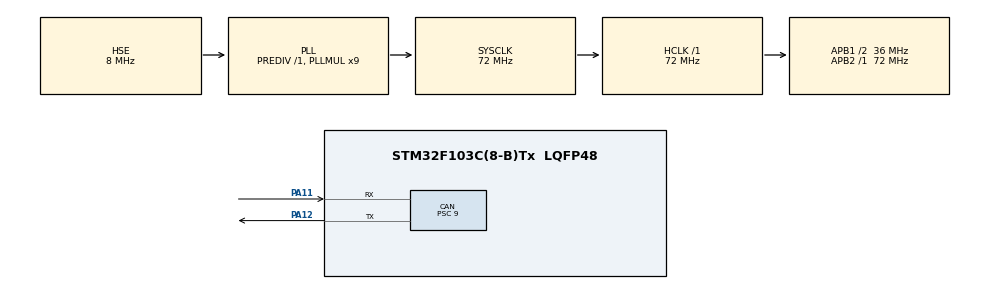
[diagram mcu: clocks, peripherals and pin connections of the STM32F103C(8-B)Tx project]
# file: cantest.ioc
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CAN.BS1=CAN_BS1_2TQ
CAN.CalculateBaudRate=1000000
CAN.CalculateTimeBit=1000
CAN.CalculateTimeQuantum=250.0
CAN.Prescaler=9
Mcu.Family=STM32F1
Mcu.Name=STM32F103C(8-B)Tx
Mcu.Package=LQFP48
NVIC.PriorityGroup=NVIC_PRIORITYGROUP_4
NVIC.TIM3_IRQn=true\:0\:0\:false\:false\:true\:true\:true\:true
NVIC.TIM4_IRQn=true\:0\:0\:false\:false\:true\:true\:true\:true
NVIC.USB_HP_CAN1_TX_IRQn=true\:0\:0\:false\:false\:true\:true\:true\:true
NVIC.USB_LP_CAN1_RX0_IRQn=true\:0\:0\:false\:false\:true\:true\:true\:true
PA11.Mode=CAN_Activate
PA11.Signal=CAN_RX
PA12.Mode=CAN_Activate
PA12.Signal=CAN_TX
PA13.Mode=Serial_Wire
PA13.Signal=SYS_JTMS-SWDIO
PA14.Mode=Serial_Wire
PA14.Signal=SYS_JTCK-SWCLK
PD0-OSC_IN.Mode=HSE-External-Oscillator
PD0-OSC_IN.Signal=RCC_OSC_IN
PD1-OSC_OUT.Mode=HSE-External-Oscillator
PD1-OSC_OUT.Signal=RCC_OSC_OUT
ProjectManager.HeapSize=0x200
ProjectManager.StackSize=0x400
ProjectManager.TargetToolchain=STM32CubeIDE
RCC.AHBFreq_Value=72000000
RCC.APB1CLKDivider=RCC_HCLK_DIV2
RCC.APB1Freq_Value=36000000
RCC.APB1TimFreq_Value=72000000
RCC.APB2Freq_Value=72000000
RCC.APB2TimFreq_Value=72000000
RCC.HCLKFreq_Value=72000000
RCC.PLLMUL=RCC_PLL_MUL9
RCC.PLLSourceVirtual=RCC_PLLSOURCE_HSE
RCC.SYSCLKFreq_VALUE=72000000
RCC.SYSCLKSource=RCC_SYSCLKSOURCE_PLLCLK
RCC.USBFreq_Value=72000000
TIM3.Period=2000
TIM3.Prescaler=72-1
TIM4.Period=2000-1
TIM4.Prescaler=71
VP_TIM3_VS_ClockSourceINT.Mode=Internal
VP_TIM4_VS_ClockSourceINT.Mode=Internal
board=custom

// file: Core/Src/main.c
/* USER CODE BEGIN Header */
/**
  ******************************************************************************
  * @file           : main.c
  * @brief          : Main program body
  ******************************************************************************
  * @attention
  *
  * Copyright (c) 2025 STMicroelectronics.
  * All rights reserved.
  *
  * This software is licensed under terms that can be found in the LICENSE file
  * in the root directory of this software component.
  * If no LICENSE file comes with this software, it is provided AS-IS.
  *
  ******************************************************************************
  */
/* USER CODE END Header */
#include "main.h"

/* USER CODE BEGIN Includes */
#include "string.h"
#include "kinematic.h"
/* USER CODE END Includes */

/* USER CODE BEGIN PTD */
typedef struct{
	int8_t FL;
	int8_t FR;
	int8_t RL;
	int8_t RR;
}Dwheel;
/* USER CODE END PTD */

/* USER CODE BEGIN PM */
//receive canbus data
uint8_t rxData[8];

//trasmit canbus data
int32_t TxMailbox;
int8_t tx_123[8];
int8_t tx_124[8];
int8_t can_tx[8]={0};

/* Pose to send */ //example data send
float pose_x = 1.23f;
float pose_y = 4.56f;
float pose_theta = 7.89f;

//wheel speed
float wheel_speed[4];
float vx=0.0f, vy =0.0f,omega =0.0f,r =0.122f;
float x=0.0f,y=0.0f,theta =0.0f;
float x_dir=0.0f,y_dir=0.0f,theta_dir =0.0f;
volatile Dwheel can;
uint8_t state =1;
/* USER CODE END PM */

CAN_HandleTypeDef hcan;

TIM_HandleTypeDef htim3;
TIM_HandleTypeDef htim4;

/* USER CODE BEGIN PV */

CAN_RxHeaderTypeDef RxHeader;
CAN_TxHeaderTypeDef TxHeader;

OMNIWHEEL omni;
CONTROLLER controller;
CONTROL_POSE pose_dir;

/* USER CODE END PV */

void SystemClock_Config(void);
static void MX_GPIO_Init(void);
static void MX_CAN_Init(void);
static void MX_TIM3_Init(void);
static void MX_TIM4_Init(void);

/* USER CODE BEGIN 0 */
void can_data_send(void){
	Dwheel can ={
		.FL =(int8_t)(wheel_speed[0]/6),
		.RL =(int8_t)(wheel_speed[2]/6),
		.FR =(int8_t)(wheel_speed[1]/6),
		.RR =(int8_t)(wheel_speed[3]/6),
	};
	TxHeader.StdId = 0x001;
	TxHeader.DLC = 8;
	memcpy(can_tx,&can, sizeof(Dwheel));
	HAL_CAN_AddTxMessage(&hcan, &TxHeader, can_tx, &TxMailbox);
}
void HAL_CAN_RxFifo0MsgPendingCallback(CAN_HandleTypeDef *hcan)
{
    CAN_RxHeaderTypeDef rxHeader;

    if (HAL_CAN_GetRxMessage(hcan, CAN_RX_FIFO0, &rxHeader, rxData) == HAL_OK)
    {
        if (rxHeader.StdId == 0x123 && rxHeader.DLC == 8)
        {
            // First frame: x, y
            memcpy(&x, &rxData[0], 4);
            memcpy(&y, &rxData[4], 4);
        }

        if (rxHeader.StdId == 0x124 && rxHeader.DLC == 4)
        {
            // Second frame: theta
            memcpy(&theta, &rxData[0], 4);
        }
    }
}

void HAL_TIM_PeriodElapsedCallback(TIM_HandleTypeDef* htim){
	if(htim->Instance == TIM3){
	controller.vx = vx;
	controller.vy = vy;
	controller.omega = omega;
	pose_dir.x=x_dir;
	pose_dir.y=y_dir;
	pose_dir.theta=theta_dir;

	omni45_kinematic2(&controller, &omni, wheel_speed);
	//omni45_kinematic_pose(&pose_dir, &omni, wheel_speed);
	}
	if(htim->Instance == TIM4){
//		TxHeader.StdId = 0x123;
//		TxHeader.DLC = 8;
//	    memcpy(&tx_123[0], &pose_x, 4);
//	    memcpy(&tx_123[4], &pose_y, 4);
//	    HAL_CAN_AddTxMessage(&hcan, &TxHeader, tx_123, &TxMailbox);
//	    TxHeader.StdId = 0x124;
//	    TxHeader.DLC = 4;
//	    memcpy(&tx_124[0], &pose_theta, 4);
//	    HAL_CAN_AddTxMessage(&hcan, &TxHeader, tx_124, &TxMailbox);
		can_data_send();
	}

}

/* USER CODE END 0 */

int main(void)
{

  /* MCU Configuration--------------------------------------------------------*/

  /* Reset of all peripherals, Initializes the Flash interface and the Systick. */
  HAL_Init();

  /* Configure the system clock */
  SystemClock_Config();

  /* Initialize all configured peripherals */
  MX_GPIO_Init();
  MX_CAN_Init();
  MX_TIM3_Init();
  MX_TIM4_Init();
  /* USER CODE BEGIN 2 */

  HAL_CAN_Start(&hcan);
  HAL_TIM_Base_Start_IT(&htim3);
  HAL_TIM_Base_Start_IT(&htim4);
  HAL_CAN_ActivateNotification(&hcan, CAN_IT_RX_FIFO0_MSG_PENDING);
  //test_omni_set_motor_speed_90(&omni, &controller, wheel_speed);
  omni_init(&omni);

  TxHeader.IDE   = CAN_ID_STD;  // Standard ID
  TxHeader.RTR   = CAN_RTR_DATA;

  /* USER CODE END 2 */

  /* Infinite loop */
  while (1)
  {

    /* USER CODE BEGIN 3 */

	/* if (state == 1){
		 //HAL_Delay(500);
		 vx = 0;
		 vy =0;
		 omega =0;
		 HAL_Delay(1000);

	 }
	 else if(state == 2){
		 vx = 2;
		 vy =0;
		 omega =0;\
		 HAL_Delay(1000);
	 }
	 else if(state ==3 ){
		 vx = 0;
		 vy =2;
	     omega =0;}

*/
	  vx = 0;
	  vy =0;
	  omega =0;
	  HAL_Delay(5000);
//	  vx = 0.4;
//	  vy =0;
//	  omega =0;
//	  HAL_Delay(500);
//	  vx = 0.88;
//	  vy =0;
//	  omega =0;
//	  HAL_Delay(500);

	  vx = 0.5;
	  vy =0;
	  omega =3.14/1.37;
	  HAL_Delay(2000);
/*
	 	  vx = -0.8;
	 	  vy =-0.8;
	 	  omega =0;
	 HAL_Delay(2000);

//	 	  vx = 0.44;
//	 	  vy =0;
//	 	  omega =0;
//	 	  HAL_Delay(500);
	  vx = 0.8;
	 	  vy =0.8;
	 	  omega =0;
	 HAL_Delay(2000);
	  vx = -0.8;
	 	  vy =0.8;
	 	  omega =0;
	 HAL_Delay(2000);*/

	 	vx = 0;
	 	vy =0;
	 	omega =0;
	 HAL_Delay(2000);

  }
  /* USER CODE END 3 */
}

void SystemClock_Config(void)
{
  RCC_OscInitTypeDef RCC_OscInitStruct = {0};
  RCC_ClkInitTypeDef RCC_ClkInitStruct = {0};

  /** Initializes the RCC Oscillators according to the specified parameters
  * in the RCC_OscInitTypeDef structure.
  */
  RCC_OscInitStruct.OscillatorType = RCC_OSCILLATORTYPE_HSE;
  RCC_OscInitStruct.HSEState = RCC_HSE_ON;
  RCC_OscInitStruct.HSEPredivValue = RCC_HSE_PREDIV_DIV1;
  RCC_OscInitStruct.HSIState = RCC_HSI_ON;
  RCC_OscInitStruct.PLL.PLLState = RCC_PLL_ON;
  RCC_OscInitStruct.PLL.PLLSource = RCC_PLLSOURCE_HSE;
  RCC_OscInitStruct.PLL.PLLMUL = RCC_PLL_MUL9;
  if (HAL_RCC_OscConfig(&RCC_OscInitStruct) != HAL_OK)
  {
    Error_Handler();
  }

  /** Initializes the CPU, AHB and APB buses clocks
  */
  RCC_ClkInitStruct.ClockType = RCC_CLOCKTYPE_HCLK|RCC_CLOCKTYPE_SYSCLK
                              |RCC_CLOCKTYPE_PCLK1|RCC_CLOCKTYPE_PCLK2;
  RCC_ClkInitStruct.SYSCLKSource = RCC_SYSCLKSOURCE_PLLCLK;
  RCC_ClkInitStruct.AHBCLKDivider = RCC_SYSCLK_DIV1;
  RCC_ClkInitStruct.APB1CLKDivider = RCC_HCLK_DIV2;
  RCC_ClkInitStruct.APB2CLKDivider = RCC_HCLK_DIV1;

  if (HAL_RCC_ClockConfig(&RCC_ClkInitStruct, FLASH_LATENCY_2) != HAL_OK)
  {
    Error_Handler();
  }
}

static void MX_CAN_Init(void)
{

  hcan.Instance = CAN1;
  hcan.Init.Prescaler = 9;
  hcan.Init.Mode = CAN_MODE_NORMAL;
  hcan.Init.SyncJumpWidth = CAN_SJW_1TQ;
  hcan.Init.TimeSeg1 = CAN_BS1_2TQ;
  hcan.Init.TimeSeg2 = CAN_BS2_1TQ;
  hcan.Init.TimeTriggeredMode = DISABLE;
  hcan.Init.AutoBusOff = DISABLE;
  hcan.Init.AutoWakeUp = DISABLE;
  hcan.Init.AutoRetransmission = DISABLE;
  hcan.Init.ReceiveFifoLocked = DISABLE;
  hcan.Init.TransmitFifoPriority = DISABLE;
  if (HAL_CAN_Init(&hcan) != HAL_OK)
  {
    Error_Handler();
  }
  /* USER CODE BEGIN CAN_Init 2 */
  CAN_FilterTypeDef filter;

    filter.FilterActivation = ENABLE;
    filter.FilterBank = 0;
    filter.FilterFIFOAssignment = CAN_FILTER_FIFO0;
    filter.FilterIdHigh = 0x0000;
    filter.FilterIdLow = 0x0000;
    filter.FilterMaskIdHigh = 0x0000;
    filter.FilterMaskIdLow = 0x0000;
    filter.FilterMode = CAN_FILTERMODE_IDMASK;
    filter.FilterScale = CAN_FILTERSCALE_32BIT;

    HAL_CAN_ConfigFilter(&hcan, &filter);
  /* USER CODE END CAN_Init 2 */

}

static void MX_TIM3_Init(void)
{

  TIM_ClockConfigTypeDef sClockSourceConfig = {0};
  TIM_MasterConfigTypeDef sMasterConfig = {0};

  htim3.Instance = TIM3;
  htim3.Init.Prescaler = 72-1;
  htim3.Init.CounterMode = TIM_COUNTERMODE_UP;
  htim3.Init.Period = 2000;
  htim3.Init.ClockDivision = TIM_CLOCKDIVISION_DIV1;
  htim3.Init.AutoReloadPreload = TIM_AUTORELOAD_PRELOAD_DISABLE;
  if (HAL_TIM_Base_Init(&htim3) != HAL_OK)
  {
    Error_Handler();
  }
  sClockSourceConfig.ClockSource = TIM_CLOCKSOURCE_INTERNAL;
  if (HAL_TIM_ConfigClockSource(&htim3, &sClockSourceConfig) != HAL_OK)
  {
    Error_Handler();
  }
  sMasterConfig.MasterOutputTrigger = TIM_TRGO_RESET;
  sMasterConfig.MasterSlaveMode = TIM_MASTERSLAVEMODE_DISABLE;
  if (HAL_TIMEx_MasterConfigSynchronization(&htim3, &sMasterConfig) != HAL_OK)
  {
    Error_Handler();
  }

}

static void MX_TIM4_Init(void)
{

  TIM_ClockConfigTypeDef sClockSourceConfig = {0};
  TIM_MasterConfigTypeDef sMasterConfig = {0};

  htim4.Instance = TIM4;
  htim4.Init.Prescaler = 71;
  htim4.Init.CounterMode = TIM_COUNTERMODE_UP;
  htim4.Init.Period = 2000-1;
  htim4.Init.ClockDivision = TIM_CLOCKDIVISION_DIV1;
  htim4.Init.AutoReloadPreload = TIM_AUTORELOAD_PRELOAD_DISABLE;
  if (HAL_TIM_Base_Init(&htim4) != HAL_OK)
  {
    Error_Handler();
  }
  sClockSourceConfig.ClockSource = TIM_CLOCKSOURCE_INTERNAL;
  if (HAL_TIM_ConfigClockSource(&htim4, &sClockSourceConfig) != HAL_OK)
  {
    Error_Handler();
  }
  sMasterConfig.MasterOutputTrigger = TIM_TRGO_RESET;
  sMasterConfig.MasterSlaveMode = TIM_MASTERSLAVEMODE_DISABLE;
  if (HAL_TIMEx_MasterConfigSynchronization(&htim4, &sMasterConfig) != HAL_OK)
  {
    Error_Handler();
  }

}

static void MX_GPIO_Init(void)
{

  /* GPIO Ports Clock Enable */
  __HAL_RCC_GPIOD_CLK_ENABLE();
  __HAL_RCC_GPIOA_CLK_ENABLE();

}

void Error_Handler(void)
{
  __disable_irq();
  while (1)
  {
  }
}
